# GD32F20x register map
File version: 1.0
CPU: CM3 r2p1, little endian, no MPU, no FPU, 4 interrupt priority bits
Registers are 32-bit, read-write, reset 0x0 unless marked. A register's access mark holds for its fields unless they carry their own. Offsets are from the block's base; [hi:lo] are bit positions; {n}, {i} and the like mark numbered series.

## HAU — HAU acceleration unit
Base 0x50060400
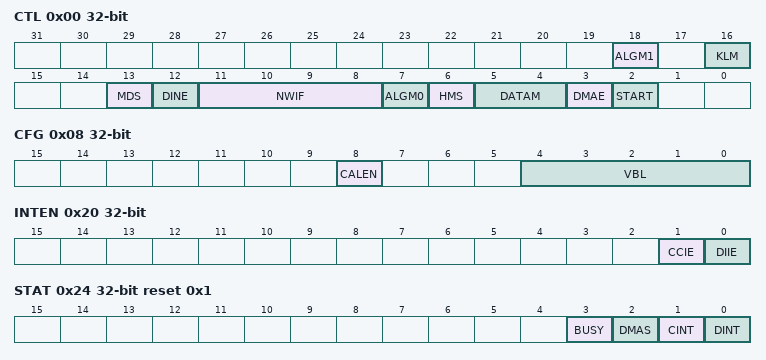
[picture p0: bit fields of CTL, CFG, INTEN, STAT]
0x00 CTL access per field — HAU control register
  [18] ALGM1 rw — Algorithm selection bit 1
  [16] KLM rw — Key length mode
  [13] MDS rw — Multiple DMA selection
  [12] DINE ro — DI register is not empty
  [11:8] NWIF ro — Number of words in IN FIFO
  [7] ALGM0 rw — Algorithm selection bit 0
  [6] HMS rw — HAU mode selection
  [5:4] DATAM rw — Data type mode
  [3] DMAE rw — DMA enable
  [2] START wo — Start message digest calculation
0x04 DI — HAU data input register
  [31:0] DI — Message data input
0x08 CFG access per field — HAU configuration register
  [8] CALEN wo — Digest calculation enable
  [4:0] VBL rw — Valid bits length in the last word
{0xC+4i} DO{i} ro (i=0..4) — HAU data output register
  [31:0] DO{i} — message digest result of hash algorithm
0x20 INTEN — HAU interrupt enable register
  [1] CCIE — calculation completion interrupt enable
  [0] DIIE — Data input interrupt enable
0x24 STAT access per field reset 0x1 — HAU status and interrupt flag register
  [3] BUSY ro — Busy flag bit
  [2] DMAS ro — DMA status flag
  [1] CINT rw — Digest calculation completion interrupt flag
  [0] DINT rw — Data input interrupt status flag
{0x310+4i} DO{i} ro (i=5..7) — HAU data output register
  [31:0] DO{i} — message digest result of hash algorithm

## I2C0 — Inter integrated circuit
Base 0x40005400
Same registers: I2C1 0x40005800, I2C2 0x4000C000
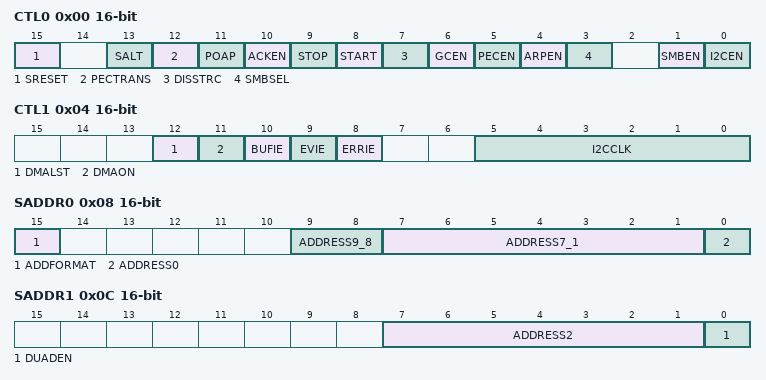
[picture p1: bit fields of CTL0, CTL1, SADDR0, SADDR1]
0x00 CTL0 16-bit — Control register 0
  [15] SRESET — Software reset
  [13] SALT — SMBus alert
  [12] PECTRANS — PEC Transfer
  [11] POAP — Position of ACK and PEC when receiving
  [10] ACKEN — Whether or not to send an ACK
  [9] STOP — Generate a STOP condition on I2C bus
  [8] START — Generate a START condition on I2C bus
  [7] DISSTRC — Whether to stretch SCL low when data is not ready in slave mode
  [6] GCEN — Whether or not to response to a General Call (0x00)
  [5] PECEN — PEC Calculation Switch
  [4] ARPEN — ARP protocol in SMBus switch
  [3] SMBSEL — SMBusType Selection
  [1] SMBEN — SMBus/I2C mode switch
  [0] I2CEN — I2C peripheral enable
0x04 CTL1 16-bit — Control register 1
  [12] DMALST — Flag indicating DMA last transfer
  [11] DMAON — DMA mode switch
  [10] BUFIE — Buffer interrupt enable
  [9] EVIE — Event interrupt enable
  [8] ERRIE — Error interrupt enable
  [5:0] I2CCLK — I2C Peripheral clock frequency
0x08 SADDR0 16-bit — Slave address register 0
  [15] ADDFORMAT — Address mode for the I2C slave
  [9:8] ADDRESS9_8 — Highest two bits of a 10-bit address
  [7:1] ADDRESS7_1 — 7-bit address or bits 7:1 of a 10-bit address
  [0] ADDRESS0 — Bit 0 of a 10-bit address
0x0C SADDR1 16-bit — Slave address register 1
  [7:1] ADDRESS2 — Second I2C address for the slave in Dual-Address mode
  [0] DUADEN — Dual-Address mode switch
0x10 DATA 16-bit — Transfer buffer register
  [7:0] TRB — Transmission or reception data buffer
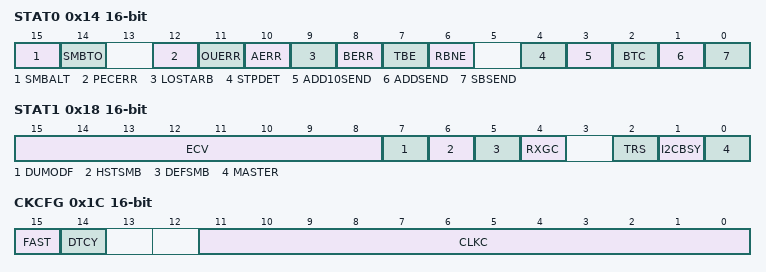
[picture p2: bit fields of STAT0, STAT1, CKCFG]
0x14 STAT0 16-bit access per field — Transfer status register 0
  [15] SMBALT rw — SMBus Alert status
  [14] SMBTO rw — Timeout signal in SMBus mode
  [12] PECERR rw — PEC error when receiving data
  [11] OUERR rw — Over-run or under-run situation occurs in slave mode
  [10] AERR rw — Acknowledge error
  [9] LOSTARB rw — Arbitration Lost in master mode
  [8] BERR rw — A bus error occurs indication a unexpected START or STOP condition on I2C bus
  [7] TBE ro — I2C_DATA is Empty during transmitting
  [6] RBNE ro — I2C_DATA is not Empty during receiving
  [4] STPDET ro — STOP condition detected in slave mode
  [3] ADD10SEND ro — Header of 10-bit address is sent in master mode
  [2] BTC ro — Byte transmission completed
  [1] ADDSEND ro — Address is sent in master mode or received and matches in slave mode
  [0] SBSEND ro — START condition sent out in master mode
0x18 STAT1 16-bit ro — Transfer status register 1
  [15:8] ECV — Packet Error Checking Value that calculated by hardware when PEC is enabled
  [7] DUMODF — Dual Flag in slave mode
  [6] HSTSMB — SMBus Host Header detected in slave mode
  [5] DEFSMB — Default address of SMBusDevice
  [4] RXGC — General call address (00h) received
  [2] TRS — Whether the I2C is a transmitter or a receiver
  [1] I2CBSY — Busy flag
  [0] MASTER — A flag indicating whether I2C block is in master or slave mode
0x1C CKCFG 16-bit — Clock configure register
  [15] FAST — I2C speed selection in master mode
  [14] DTCY — Duty cycle in fast mode
  [11:0] CLKC — I2C Clock control in master mode
0x20 RT 16-bit reset 0x2 — Rise time register
  [5:0] RISETIME — Maximum rise time in master mode
